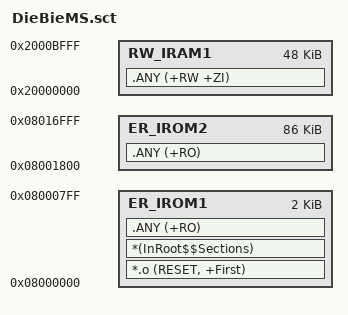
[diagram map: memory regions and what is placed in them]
; *************************************************************
; *** Scatter-Loading Description File generated by uVision ***
; *************************************************************

LR_IROM1 0x08000000 0x00000800  {    ; load region size_region
  ER_IROM1 0x08000000 0x00000800  {  ; load address = execution address
   *.o (RESET, +First)
   *(InRoot$$Sections)
   .ANY (+RO)
  }
  RW_IRAM1 0x20000000 0x0000C000  {  ; RW data
   .ANY (+RW +ZI)
  }
}

LR_IROM2 0x08001800 0x00015800  {
  ER_IROM2 0x08001800 0x00015800  {  ; load address = execution address
   .ANY (+RO)
  }
}
